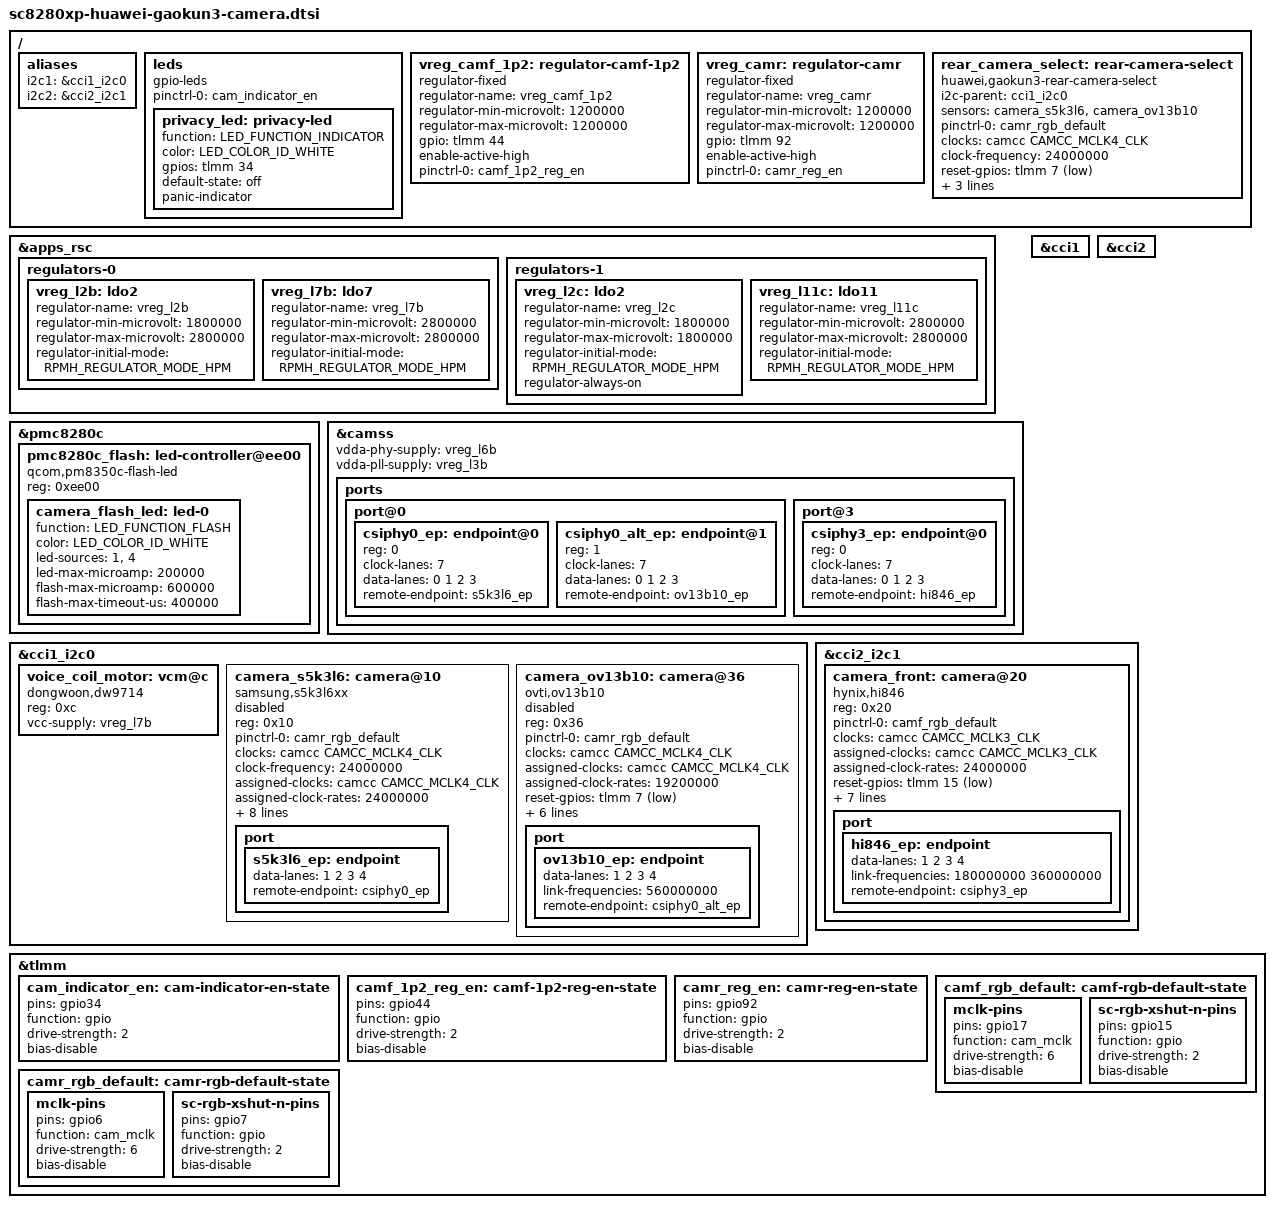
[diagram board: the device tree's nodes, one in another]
// SPDX-License-Identifier: BSD-3-Clause
/*
 * Copyright (c) 2021, The Linux Foundation. All rights reserved.
 */

#include <dt-bindings/leds/common.h>

/* remove due to gpio pins collision, skip 2nd instance won't break things */
/delete-node/ &cci1_i2c1;
/delete-node/ &cci1_i2c1_default;
/delete-node/ &cci1_i2c1_sleep;

/* override */
/delete-node/ &vreg_l2b;

/ {
	aliases {
		i2c1 = &cci1_i2c0;
		i2c2 = &cci2_i2c1;
	};

	leds {
		compatible = "gpio-leds";

		pinctrl-0 = <&cam_indicator_en>;
		pinctrl-names = "default";

		privacy_led: privacy-led {
			function = LED_FUNCTION_INDICATOR;
			color = <LED_COLOR_ID_WHITE>;
			gpios = <&tlmm 34 GPIO_ACTIVE_HIGH>;
			default-state = "off";
			panic-indicator;
		};

		/*
		 * GPIO93 used to drive a "white:flash" gpio-led here. It does not
		 * light (measured) and it shadows the name a userspace flash
		 * control looks for; the real flash is the PMIC one below.
		 */
	};

	vreg_camf_1p2: regulator-camf-1p2 {
		compatible = "regulator-fixed";

		regulator-name = "vreg_camf_1p2";
		regulator-min-microvolt = <1200000>;
		regulator-max-microvolt = <1200000>;

		gpio = <&tlmm 44 GPIO_ACTIVE_HIGH>;
		enable-active-high;

		pinctrl-0 = <&camf_1p2_reg_en>;
		pinctrl-names = "default";
	};

	vreg_camr: regulator-camr {
		compatible = "regulator-fixed";

		regulator-name = "vreg_camr";
		/*
		 * Rear sensor digital core rail, gated by GPIO92 (Windows
		 * CAMS_RES_QRD). The board LDO sets the real voltage; 1.2V is
		 * the OV13B10 DVDD nominal.
		 */
		regulator-min-microvolt = <1200000>;
		regulator-max-microvolt = <1200000>;

		gpio = <&tlmm 92 GPIO_ACTIVE_HIGH>;
		enable-active-high;

		pinctrl-0 = <&camr_reg_en>;
		pinctrl-names = "default";
	};
};

&apps_rsc {
	regulators-0 {
		vreg_l2b: ldo2 {
			regulator-name = "vreg_l2b";
			regulator-min-microvolt = <1800000>;
			regulator-max-microvolt = <2800000>;
			regulator-initial-mode = <RPMH_REGULATOR_MODE_HPM>;
		};

		vreg_l7b: ldo7 {
			regulator-name = "vreg_l7b";
			regulator-min-microvolt = <2800000>;
			regulator-max-microvolt = <2800000>;
			regulator-initial-mode = <RPMH_REGULATOR_MODE_HPM>;
		};
	};

	regulators-1 {
		vreg_l2c: ldo2 {
			regulator-name = "vreg_l2c";
			regulator-min-microvolt = <1800000>;
			regulator-max-microvolt = <1800000>;
			regulator-initial-mode = <RPMH_REGULATOR_MODE_HPM>;
			/* may be used in audio codec driver (ACD) too */
			// regulator-allow-set-load;
			// regulator-allowed-modes = <RPMH_REGULATOR_MODE_LPM
			// 			   RPMH_REGULATOR_MODE_HPM>;
			regulator-always-on;
		};

		vreg_l11c: ldo11 {
			regulator-name = "vreg_l11c";
			regulator-min-microvolt = <2800000>;
			regulator-max-microvolt = <2800000>;
			regulator-initial-mode = <RPMH_REGULATOR_MODE_HPM>;
		};
	};
};

/*
 * Flash. The Windows \_SB.FLSH device has no GPIO/I2C resources, so the torch
 * runs through the PMIC flash module (pmc8280c is a PM8350C, driver
 * leds-qcom-flash); driving GPIO93 directly does not light it. Measured by
 * lighting each channel in turn: the white LED is on channels 1 and 4. The
 * current limits are conservative assumptions, not module datasheet values.
 * flash-leds is deliberately not set on the sensor node: it would make
 * v4l2-async wait for another subdev.
 */
&pmc8280c {
	pmc8280c_flash: led-controller@ee00 {
		compatible = "qcom,pm8350c-flash-led", "qcom,spmi-flash-led";
		reg = <0xee00>;

		camera_flash_led: led-0 {
			function = LED_FUNCTION_FLASH;
			color = <LED_COLOR_ID_WHITE>;
			led-sources = <1>, <4>;
			led-max-microamp = <200000>;
			flash-max-microamp = <600000>;
			flash-max-timeout-us = <400000>;
		};
	};
};

&camss {
	/*
	 * CSIPHY0, CSIPHY1 1.2v = l4d, 0.88v = l6d
	 * CSIPHY2, CSIPHY3 1.2v = l3b, 0.88v = l6b
	 *
	 * drivers/media/platform/qcom/camss/camss.c
	 */

	vdda-phy-supply = <&vreg_l6b>;
	vdda-pll-supply = <&vreg_l3b>;

	status = "okay";

	ports {
		/*
		 * port@0: csiphy0, the rear camera. The board is built with one
		 * of two interchangeable modules, an ofilm OV13B10 or a lijing
		 * S5K3L6, so both endpoints are described and CAMSS completes
		 * with whichever one binds; rear_camera_select below decides
		 * that by registering the matching sensor node only. CAMSS takes
		 * the CSIPHY index from the port number (camss_parse_endpoint_node),
		 * so both candidates land on csiphy0.
		 *
		 * Power, from the board's own table (Windows CAMS_RES_QRD.bin):
		 * LDO2_B 2.8V (vdda), LDO2_C 1.8V (vddio), the GPIO92-gated
		 * core rail (vddd), reset GPIO7, MCLK4. LDO2_B is shared with
		 * the panel's vddi, which votes 1.8V; the drivers raise it while
		 * the module is powered.
		 */
		port@0 {
			csiphy0_ep: endpoint@0 {
				reg = <0>;

				clock-lanes = <7>;
				data-lanes = <0 1 2 3>;
				remote-endpoint = <&s5k3l6_ep>;
			};

			csiphy0_alt_ep: endpoint@1 {
				reg = <1>;

				clock-lanes = <7>;
				data-lanes = <0 1 2 3>;
				remote-endpoint = <&ov13b10_ep>;
			};
		};

		port@3 {
			csiphy3_ep: endpoint@0 {
				reg = <0>;

				clock-lanes = <7>;
				data-lanes = <0 1 2 3>;
				remote-endpoint = <&hi846_ep>;
			};
		};
	};
};

&cci1 {
	status = "okay";
};

&cci1_i2c0 {
	voice_coil_motor: vcm@c {
		compatible = "dongwoon,dw9714";
		reg = <0xc>;
		vcc-supply = <&vreg_l7b>; /* FIXME: require l2c on first */
	};

	/*
	 * The two rear camera modules this board is built with, at the
	 * addresses their drivers expect. Both stay disabled: enabled, they
	 * would claim the same reset line -- gpiolib hands it to one consumer
	 * only, so the driver that loses that race fails on -EBUSY rather than
	 * on the hardware it does not have -- and set the rate of the one MCLK4
	 * against each other. rear_camera_select below powers the module, reads
	 * these two id registers and registers only the node that answered. The
	 * Windows driver package names them ofilm_ov13b10 and lijing_s5k3l6.
	 *
	 * Rails from CAMS_RES_QRD.bin: LDO2_B 2.8V (vdda, shared with the
	 * panel's 1.8V vddi - the drivers raise it while powered), LDO2_C 1.8V
	 * (vddio), the GPIO92-gated core rail (vddd), reset GPIO7, MCLK4.
	 */
	camera_s5k3l6: camera@10 {
		compatible = "samsung,s5k3l6xx";
		reg = <0x10>;
		status = "disabled";

		pinctrl-0 = <&camr_rgb_default>;
		pinctrl-names = "default";

		clocks = <&camcc CAMCC_MCLK4_CLK>;
		clock-names = "mclk";
		clock-frequency = <24000000>;

		assigned-clocks = <&camcc CAMCC_MCLK4_CLK>;
		assigned-clock-rates = <24000000>;

		rstn-gpios = <&tlmm 7 GPIO_ACTIVE_LOW>;

		vddio-supply = <&vreg_l2c>;
		vdda-supply = <&vreg_l2b>;
		vddd-supply = <&vreg_camr>;

		leds = <&privacy_led>;
		led-names = "privacy";

		orientation = <1>;
		/*
		 * Counter-clockwise (video-interface-devices.yaml). Confirmed on
		 * device: preview upright, SENSOR_ORIENTATION 180.
		 */
		rotation = <180>;

		port {
			s5k3l6_ep: endpoint {
				data-lanes = <1 2 3 4>;
				remote-endpoint = <&csiphy0_ep>;
			};
		};
	};

	camera_ov13b10: camera@36 {
		compatible = "ovti,ov13b10";
		reg = <0x36>;
		status = "disabled";

		pinctrl-0 = <&camr_rgb_default>;
		pinctrl-names = "default";

		clocks = <&camcc CAMCC_MCLK4_CLK>;
		assigned-clocks = <&camcc CAMCC_MCLK4_CLK>;
		assigned-clock-rates = <19200000>;

		reset-gpios = <&tlmm 7 GPIO_ACTIVE_LOW>;

		avdd-supply = <&vreg_l2b>;
		dovdd-supply = <&vreg_l2c>;
		dvdd-supply = <&vreg_camr>;

		lens-focus = <&voice_coil_motor>;

		orientation = <1>;
		/* Same module orientation as the S5K3L6; see the node above. */
		rotation = <180>;

		port {
			ov13b10_ep: endpoint {
				data-lanes = <1 2 3 4>;
				link-frequencies = /bits/ 64 <560000000>;
				remote-endpoint = <&csiphy0_alt_ep>;
			};
		};
	};

	// eeprom@50/51 <= l2c
};

/*
 * Rear camera module selector, see gaokun3-camera-select.c: it runs the
 * module's power sequence once, reads the id registers of the two candidates
 * above and registers only the node whose module answered, so one device tree
 * and one kernel serve both module variants. Its supplies, clock and reset are
 * the same ones the sensor nodes carry, because the sequence has to run before
 * either sensor driver can be bound.
 */
/ {
	rear_camera_select: rear-camera-select {
		compatible = "huawei,gaokun3-rear-camera-select";

		i2c-parent = <&cci1_i2c0>;
		sensors = <&camera_s5k3l6>, <&camera_ov13b10>;

		pinctrl-0 = <&camr_rgb_default>;
		pinctrl-names = "default";

		clocks = <&camcc CAMCC_MCLK4_CLK>;
		clock-names = "mclk";
		clock-frequency = <24000000>;

		reset-gpios = <&tlmm 7 GPIO_ACTIVE_LOW>;

		vdda-supply = <&vreg_l2b>;
		vddio-supply = <&vreg_l2c>;
		vddd-supply = <&vreg_camr>;
	};
};

&cci2 {
	status = "okay";
};

&cci2_i2c1 {
	// ??? @10 appears when CAMCC_MCLK3_CLK@19.2MHz
	// On 2023 model, S5K4H7@2d, image quality is better than hi846

	camera_front: camera@20 {
		compatible = "hynix,hi846";
		reg = <0x20>;

		pinctrl-0 = <&camf_rgb_default>;
		pinctrl-names = "default";

		clocks = <&camcc CAMCC_MCLK3_CLK>;

		assigned-clocks = <&camcc CAMCC_MCLK3_CLK>;
		assigned-clock-rates = <24000000>;

		reset-gpios = <&tlmm 15 GPIO_ACTIVE_LOW>;
		vddio-supply = <&vreg_l2c>;
		vdda-supply = <&vreg_l11c>;
		vddd-supply = <&vreg_camf_1p2>;

		leds = <&privacy_led>;
		led-names = "privacy";

		orientation = <0>;	/* Front facing */
		rotation = <0>;

		port {
			hi846_ep: endpoint {
				data-lanes = <1 2 3 4>;
				link-frequencies = /bits/ 64 <180000000 360000000>;
				remote-endpoint = <&csiphy3_ep>;
			};
		};
	};

	// eeprom@50
	// actuator???@58, 2023 only
};

&tlmm {
	cam_indicator_en: cam-indicator-en-state {
		pins = "gpio34";
		function = "gpio";
		drive-strength = <2>;
		bias-disable;
	};

	camf_1p2_reg_en: camf-1p2-reg-en-state {
		pins = "gpio44";
		function = "gpio";
		drive-strength = <2>;
		bias-disable;
	};

	camr_reg_en: camr-reg-en-state {
		pins = "gpio92";
		function = "gpio";
		drive-strength = <2>;
		bias-disable;
	};

	camf_rgb_default: camf-rgb-default-state {
		mclk-pins {
			pins = "gpio17";
			function = "cam_mclk";
			drive-strength = <6>;
			bias-disable;
		};

		sc-rgb-xshut-n-pins {
			pins = "gpio15";
			function = "gpio";
			drive-strength = <2>;
			bias-disable;
		};
	};

	camr_rgb_default: camr-rgb-default-state {
		mclk-pins {
			pins = "gpio6";
			function = "cam_mclk";
			drive-strength = <6>;
			bias-disable;
		};

		sc-rgb-xshut-n-pins {
			pins = "gpio7";
			function = "gpio";
			drive-strength = <2>;
			bias-disable;
		};
	};
};
